VERSION ""

NS_ :

BS_:

BU_: BMS VCU

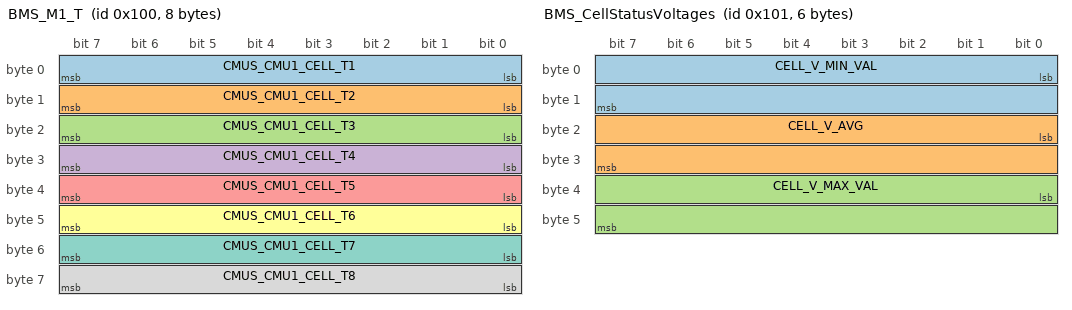
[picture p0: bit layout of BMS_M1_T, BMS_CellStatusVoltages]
BO_ 256 BMS_M1_T: 8 BMS
	SG_ CMUS_CMU1_CELL_T1 : 0|8@1- (1,0) [10|70] "degC" VCU
        SG_ CMUS_CMU1_CELL_T2 : 8|8@1- (1,0) [10|70] "degC" VCU
	SG_ CMUS_CMU1_CELL_T3 : 16|8@1- (1,0) [10|70] "degC" VCU
	SG_ CMUS_CMU1_CELL_T4 : 24|8@1- (1,0) [10|70] "degC" VCU
	SG_ CMUS_CMU1_CELL_T5 : 32|8@1- (1,0) [10|70] "degC" VCU
	SG_ CMUS_CMU1_CELL_T6 : 40|8@1- (1,0) [10|70] "degC" VCU
	SG_ CMUS_CMU1_CELL_T7 : 48|8@1- (1,0) [10|70] "degC" VCU
	SG_ CMUS_CMU1_CELL_T8 : 56|8@1- (1,0) [10|70] "degC" VCU

BO_ 257 BMS_CellStatusVoltages: 6 BMS
	SG_ CELL_V_MIN_VAL : 0|16@1+ (0.1,0) [2000|4000] "mV" VCU
	SG_ CELL_V_AVG : 16|16@1+ (0.1,0) [2000|4000] "mV" VCU
	SG_ CELL_V_MAX_VAL : 32|16@1+ (0.1,0) [2000|4000] "mV" VCU

BO_ 258 BMS_BattStatus: 4 BMS
	SG_ PACK_V_SUM_OF_CELLS : 0|16@1+ (0.1,0) [0|400] "V" VCU
	SG_ PACK_Q_SOC_TRIMMED : 16|16@1+ (0.01,0) [0|100] "%" VCU

BA_DEF_ BO_  "VFrameFormat" ENUM  "StandardCAN","ExtendedCAN","reserved","J1939PG";
BA_DEF_  "DatabaseVersion" STRING ;
BA_DEF_  "BusType" STRING ;
BA_DEF_  "ProtocolType" STRING ;
BA_DEF_  "DatabaseCompiler" STRING ;
BA_DEF_DEF_  "VFrameFormat" "StandardCAN";
BA_DEF_DEF_  "DatabaseVersion" "DEMO PLUS";
BA_DEF_DEF_  "BusType" "";
BA_DEF_DEF_  "ProtocolType" "";
BA_DEF_DEF_  "DatabaseCompiler" "";
BA_ "BusType" "CAN";
BA_ "DatabaseCompiler" "CSS ELECTRONICS (WWW.CSSELECTRONICS.COM)";
BA_ "DatabaseVersion" "1.0.0";
